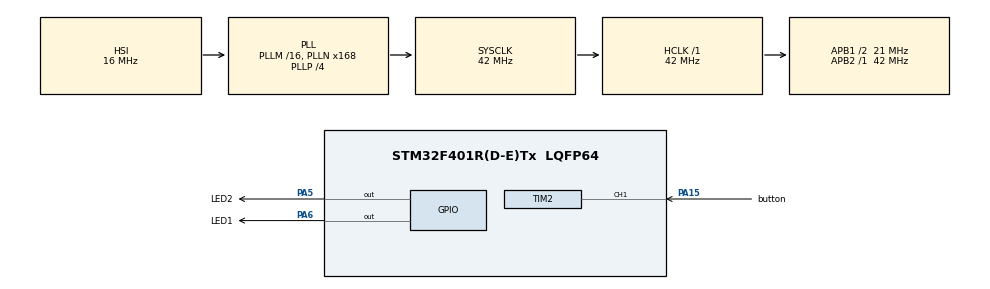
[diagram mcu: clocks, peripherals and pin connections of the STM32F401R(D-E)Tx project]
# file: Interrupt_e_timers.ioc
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Mcu.Family=STM32F4
Mcu.Name=STM32F401R(D-E)Tx
Mcu.Package=LQFP64
NVIC.PriorityGroup=NVIC_PRIORITYGROUP_4
NVIC.TIM1_TRG_COM_TIM11_IRQn=true\:0\:0\:false\:false\:true\:true\:true
NVIC.TIM2_IRQn=true\:0\:0\:false\:false\:true\:true\:true
PA13.Mode=Serial_Wire
PA13.Signal=SYS_JTMS-SWDIO
PA14.Mode=Serial_Wire
PA14.Signal=SYS_JTCK-SWCLK
PA15.GPIO_Label=button
PA15.Signal=S_TIM2_CH1_ETR
PA5.GPIO_Label=LED2
PA5.GPIO_Speed=GPIO_SPEED_FREQ_MEDIUM
PA5.Signal=GPIO_Output
PA6.GPIO_Label=LED1
PA6.Signal=GPIO_Output
PH0\ -\ OSC_IN.Mode=HSE-External-Oscillator
PH0\ -\ OSC_IN.Signal=RCC_OSC_IN
PH1\ -\ OSC_OUT.Mode=HSE-External-Oscillator
PH1\ -\ OSC_OUT.Signal=RCC_OSC_OUT
ProjectManager.HeapSize=0x200
ProjectManager.StackSize=0x400
ProjectManager.TargetToolchain=MDK-ARM V5.27
RCC.48MHZClocksFreq_Value=42000000
RCC.AHBFreq_Value=42000000
RCC.APB1CLKDivider=RCC_HCLK_DIV2
RCC.APB1Freq_Value=21000000
RCC.APB1TimFreq_Value=42000000
RCC.APB2Freq_Value=42000000
RCC.APB2TimFreq_Value=42000000
RCC.CortexFreq_Value=42000000
RCC.HCLKFreq_Value=42000000
RCC.HSE_VALUE=25000000
RCC.HSI_VALUE=16000000
RCC.LSE_VALUE=32768
RCC.PLLN=168
RCC.PLLP=RCC_PLLP_DIV4
RCC.SYSCLKFreq_VALUE=42000000
RCC.SYSCLKSource=RCC_SYSCLKSOURCE_PLLCLK
RCC.VCOOutputFreq_Value=168000000
SH.S_TIM2_CH1_ETR.0=TIM2_CH1,Input_Capture1_from_TI1
SH.S_TIM2_CH1_ETR.1=TIM2_CH1,Input_Capture2_from_TI1
TIM11.Prescaler=4199
TIM2.Channel-Input_Capture1_from_TI1=TIM_CHANNEL_1
TIM2.Channel-Input_Capture2_from_TI1=TIM_CHANNEL_2
VP_TIM11_VS_ClockSourceINT.Mode=Enable_Timer
VP_TIM2_VS_ClockSourceINT.Mode=Internal
board=custom

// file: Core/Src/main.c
/* USER CODE BEGIN Header */
/**
  ******************************************************************************
  * @file           : main.c
  * @brief          : Main program body
  ******************************************************************************
  * @attention
  *
  * <h2><center>&copy; Copyright (c) 2021 Daniel Rossi.
  * All rights reserved.</center></h2>
  *
  *
  ******************************************************************************
  */
/* USER CODE END Header */
#include "main.h"

/* USER CODE BEGIN PTD */
#define LED_INTERVAL 2000
/* USER CODE END PTD */

TIM_HandleTypeDef htim2;
TIM_HandleTypeDef htim11;

void SystemClock_Config(void);
static void MX_GPIO_Init(void);
static void MX_TIM2_Init(void);
static void MX_TIM11_Init(void);

int main(void)
{

  /* MCU Configuration--------------------------------------------------------*/

  /* Reset of all peripherals, Initializes the Flash interface and the Systick. */
  HAL_Init();

  /* Configure the system clock */
  SystemClock_Config();

  /* Initialize all configured peripherals */
  MX_GPIO_Init();
  MX_TIM2_Init();
  MX_TIM11_Init();
  /* USER CODE BEGIN 2 */

	HAL_TIM_Base_Start_IT(&htim2);
	HAL_TIM_IC_Start_IT(&htim2, TIM_CHANNEL_1);
	HAL_TIM_IC_Start_IT(&htim2, TIM_CHANNEL_2);

  HAL_TIM_Base_Start(&htim11);
  /* USER CODE END 2 */

  /* Infinite loop */
  while (1)
  {

  }
}

void SystemClock_Config(void)
{
  RCC_OscInitTypeDef RCC_OscInitStruct = {0};
  RCC_ClkInitTypeDef RCC_ClkInitStruct = {0};

  /** Configure the main internal regulator output voltage
  */
  __HAL_RCC_PWR_CLK_ENABLE();
  __HAL_PWR_VOLTAGESCALING_CONFIG(PWR_REGULATOR_VOLTAGE_SCALE2);
  /** Initializes the RCC Oscillators according to the specified parameters
  * in the RCC_OscInitTypeDef structure.
  */
  RCC_OscInitStruct.OscillatorType = RCC_OSCILLATORTYPE_HSI;
  RCC_OscInitStruct.HSIState = RCC_HSI_ON;
  RCC_OscInitStruct.HSICalibrationValue = RCC_HSICALIBRATION_DEFAULT;
  RCC_OscInitStruct.PLL.PLLState = RCC_PLL_ON;
  RCC_OscInitStruct.PLL.PLLSource = RCC_PLLSOURCE_HSI;
  RCC_OscInitStruct.PLL.PLLM = 16;
  RCC_OscInitStruct.PLL.PLLN = 168;
  RCC_OscInitStruct.PLL.PLLP = RCC_PLLP_DIV4;
  RCC_OscInitStruct.PLL.PLLQ = 4;
  if (HAL_RCC_OscConfig(&RCC_OscInitStruct) != HAL_OK)
  {
    Error_Handler();
  }
  /** Initializes the CPU, AHB and APB buses clocks
  */
  RCC_ClkInitStruct.ClockType = RCC_CLOCKTYPE_HCLK|RCC_CLOCKTYPE_SYSCLK
                              |RCC_CLOCKTYPE_PCLK1|RCC_CLOCKTYPE_PCLK2;
  RCC_ClkInitStruct.SYSCLKSource = RCC_SYSCLKSOURCE_PLLCLK;
  RCC_ClkInitStruct.AHBCLKDivider = RCC_SYSCLK_DIV1;
  RCC_ClkInitStruct.APB1CLKDivider = RCC_HCLK_DIV2;
  RCC_ClkInitStruct.APB2CLKDivider = RCC_HCLK_DIV1;

  if (HAL_RCC_ClockConfig(&RCC_ClkInitStruct, FLASH_LATENCY_1) != HAL_OK)
  {
    Error_Handler();
  }
}

static void MX_TIM2_Init(void)
{

  TIM_ClockConfigTypeDef sClockSourceConfig = {0};
  TIM_MasterConfigTypeDef sMasterConfig = {0};
  TIM_IC_InitTypeDef sConfigIC = {0};

  htim2.Instance = TIM2;
  htim2.Init.Prescaler = 0;
  htim2.Init.CounterMode = TIM_COUNTERMODE_UP;
  htim2.Init.Period = 4294967295;
  htim2.Init.ClockDivision = TIM_CLOCKDIVISION_DIV1;
  htim2.Init.AutoReloadPreload = TIM_AUTORELOAD_PRELOAD_DISABLE;
  if (HAL_TIM_Base_Init(&htim2) != HAL_OK)
  {
    Error_Handler();
  }
  sClockSourceConfig.ClockSource = TIM_CLOCKSOURCE_INTERNAL;
  if (HAL_TIM_ConfigClockSource(&htim2, &sClockSourceConfig) != HAL_OK)
  {
    Error_Handler();
  }
  if (HAL_TIM_IC_Init(&htim2) != HAL_OK)
  {
    Error_Handler();
  }
  sMasterConfig.MasterOutputTrigger = TIM_TRGO_RESET;
  sMasterConfig.MasterSlaveMode = TIM_MASTERSLAVEMODE_DISABLE;
  if (HAL_TIMEx_MasterConfigSynchronization(&htim2, &sMasterConfig) != HAL_OK)
  {
    Error_Handler();
  }
  sConfigIC.ICPolarity = TIM_INPUTCHANNELPOLARITY_RISING;
  sConfigIC.ICSelection = TIM_ICSELECTION_DIRECTTI;
  sConfigIC.ICPrescaler = TIM_ICPSC_DIV1;
  sConfigIC.ICFilter = 0;
  if (HAL_TIM_IC_ConfigChannel(&htim2, &sConfigIC, TIM_CHANNEL_1) != HAL_OK)
  {
    Error_Handler();
  }
  sConfigIC.ICSelection = TIM_ICSELECTION_INDIRECTTI;
  if (HAL_TIM_IC_ConfigChannel(&htim2, &sConfigIC, TIM_CHANNEL_2) != HAL_OK)
  {
    Error_Handler();
  }

}

static void MX_TIM11_Init(void)
{

  htim11.Instance = TIM11;
  htim11.Init.Prescaler = 4199;
  htim11.Init.CounterMode = TIM_COUNTERMODE_UP;
  htim11.Init.Period = 65535;
  htim11.Init.ClockDivision = TIM_CLOCKDIVISION_DIV1;
  htim11.Init.AutoReloadPreload = TIM_AUTORELOAD_PRELOAD_DISABLE;
  if (HAL_TIM_Base_Init(&htim11) != HAL_OK)
  {
    Error_Handler();
  }

}

static void MX_GPIO_Init(void)
{
  GPIO_InitTypeDef GPIO_InitStruct = {0};

  /* GPIO Ports Clock Enable */
  __HAL_RCC_GPIOH_CLK_ENABLE();
  __HAL_RCC_GPIOA_CLK_ENABLE();

  /*Configure GPIO pin Output Level */
  HAL_GPIO_WritePin(GPIOA, LED2_Pin|LED1_Pin, GPIO_PIN_RESET);

  /*Configure GPIO pin : LED2_Pin */
  GPIO_InitStruct.Pin = LED2_Pin;
  GPIO_InitStruct.Mode = GPIO_MODE_OUTPUT_PP;
  GPIO_InitStruct.Pull = GPIO_NOPULL;
  GPIO_InitStruct.Speed = GPIO_SPEED_FREQ_MEDIUM;
  HAL_GPIO_Init(LED2_GPIO_Port, &GPIO_InitStruct);

  /*Configure GPIO pin : LED1_Pin */
  GPIO_InitStruct.Pin = LED1_Pin;
  GPIO_InitStruct.Mode = GPIO_MODE_OUTPUT_PP;
  GPIO_InitStruct.Pull = GPIO_NOPULL;
  GPIO_InitStruct.Speed = GPIO_SPEED_FREQ_LOW;
  HAL_GPIO_Init(LED1_GPIO_Port, &GPIO_InitStruct);

}

void Error_Handler(void)
{
  __disable_irq();
  while (1)
  {
  }
}

/************************ (C) COPYRIGHT STMicroelectronics *****END OF FILE****/
